VERSION ""

NS_ :

BS_:

BU_: DRIVER MOTOR SENSOR

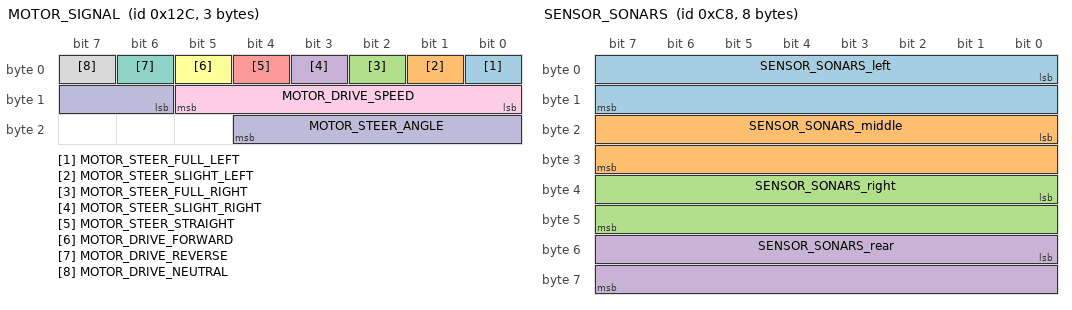
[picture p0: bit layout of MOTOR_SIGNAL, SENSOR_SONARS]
BO_ 300 MOTOR_SIGNAL: 3 DRIVER
 SG_ MOTOR_STEER_FULL_LEFT : 0|1@1+ (1,0) [0|0] "" MOTOR
 SG_ MOTOR_STEER_SLIGHT_LEFT : 1|1@1+ (1,0) [0|0] "" MOTOR
 SG_ MOTOR_STEER_FULL_RIGHT : 2|1@1+ (1,0) [0|0] "" MOTOR
 SG_ MOTOR_STEER_SLIGHT_RIGHT : 3|1@1+ (1,0) [0|0] "" MOTOR
 SG_ MOTOR_STEER_STRAIGHT : 4|1@1+ (1,0) [0|0] "" MOTOR
 SG_ MOTOR_DRIVE_FORWARD : 5|1@1+ (1,0) [0|0] "" MOTOR
 SG_ MOTOR_DRIVE_REVERSE : 6|1@1+ (1,0) [0|0] "" MOTOR
 SG_ MOTOR_DRIVE_NEUTRAL : 7|1@1+ (1,0) [0|0] "" MOTOR
 SG_ MOTOR_DRIVE_SPEED : 8|6@1+ (1,0) [0|60] "mph" MOTOR
 SG_ MOTOR_STEER_ANGLE : 14|7@1+ (1,0) [10|20] "degrees" MOTOR

BO_ 200 SENSOR_SONARS: 8 SENSOR
 SG_ SENSOR_SONARS_left : 0|16@1+ (1,0) [0|256] "" DRIVER,IO
 SG_ SENSOR_SONARS_middle : 16|16@1+ (1,0) [0|256] "" DRIVER,IO
 SG_ SENSOR_SONARS_right : 32|16@1+ (1,0) [0|256] "" DRIVER,IO
 SG_ SENSOR_SONARS_rear : 48|16@1+ (1,0) [0|256] "" DRIVER,IO
